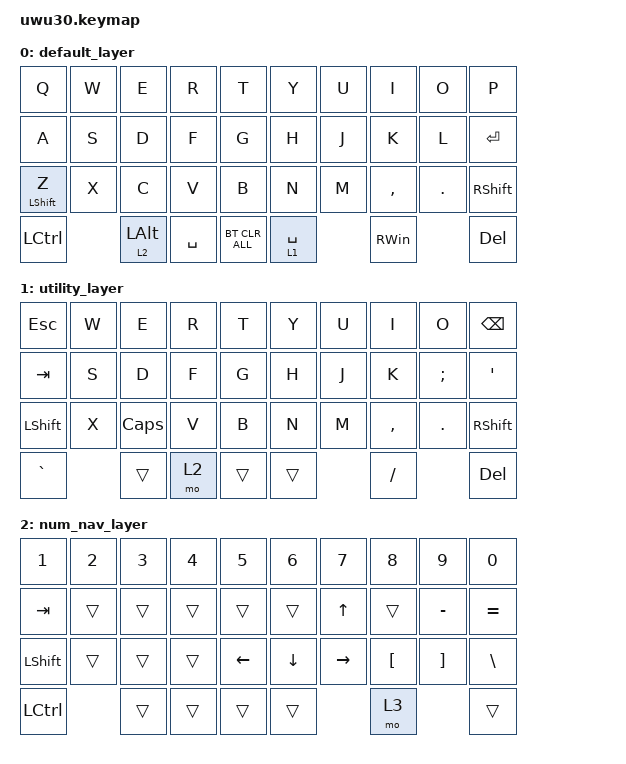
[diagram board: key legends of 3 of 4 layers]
/*
 * Copyright (c) 2023 The ZMK Contributors
 *
 * SPDX-License-Identifier: MIT
 */

#include <behaviors.dtsi>
#include <dt-bindings/zmk/keys.h>
#include <dt-bindings/zmk/bt.h>
#include <dt-bindings/zmk/outputs.h>

/ {
    combos {
        compatible = "zmk,combos";

        combo_mo1 {
            timeout-ms = <100>;
            key-positions = <1 2>;
            bindings = <&mo 1>;
        };

        combo_mo2 {
            timeout-ms = <100>;
            key-positions = <28 29>;
            bindings = <&mo 2>;
        };
    };
};

&mt {
    tapping-term-ms = <400>;
};

/ {
    keymap {
        compatible = "zmk,keymap";

        default_layer {
            bindings = <
    &kp Q           &kp W           &kp E           &kp R           &kp T           &kp Y           &kp U           &kp I           &kp O           &kp P
    &kp A           &kp S           &kp D           &kp F           &kp G           &kp H           &kp J           &kp K           &kp L           &kp ENTER
    &mt LSHIFT Z    &kp X           &kp C           &kp V           &kp B           &kp N           &kp M           &kp COMMA       &kp DOT         &kp RSHIFT
    &kp LCTRL                       &lt 2 LALT      &kp SPACE       &bt BT_CLR_ALL  &lt 1 SPACE                     &kp RWIN                        &kp DEL

            >;
        };

        utility_layer {
            bindings = <
    &kp ESC         &kp W           &kp E           &kp R           &kp T           &kp Y           &kp U           &kp I           &kp O           &kp BSPC
    &kp TAB         &kp S           &kp D           &kp F           &kp G           &kp H           &kp J           &kp K           &kp SEMI        &kp SQT
    &kp LSHIFT      &kp X           &kp CAPSLOCK    &kp V           &kp B           &kp N           &kp M           &kp COMMA       &kp DOT         &kp RSHIFT
    &kp GRAVE                       &trans          &mo 2           &trans          &trans                          &kp SLASH                       &kp DEL
            >;
        };

        num_nav_layer {
            bindings = <
    &kp N1          &kp N2          &kp N3          &kp N4          &kp N5          &kp N6          &kp N7          &kp N8          &kp N9          &kp N0
    &kp TAB         &trans          &trans          &trans          &trans          &trans          &kp UP          &trans          &kp MINUS       &kp EQUAL
    &kp LSHIFT      &trans          &trans          &trans          &kp LEFT        &kp DOWN        &kp RIGHT       &kp LBKT        &kp RBKT        &kp BACKSLASH
    &kp LCTRL                       &trans          &trans          &trans          &trans                          &mo 3                           &trans
            >;
        };

        f_layer {
            bindings = <
    &kp F1          &kp F2          &kp F3          &kp F4          &kp F5          &kp F6          &kp F7          &kp F8          &kp F9          &kp F10
    &kp F11         &kp F12         &trans          &trans          &trans          &trans          &trans          &trans          &trans          &trans
    &trans          &trans          &trans          &sys_reset      &bootloader     u&trans          &trans          &trans          &trans          &trans
    &trans                          &trans          &trans          &trans          &trans                          &trans                          &trans
            >;
        };
    };
};
